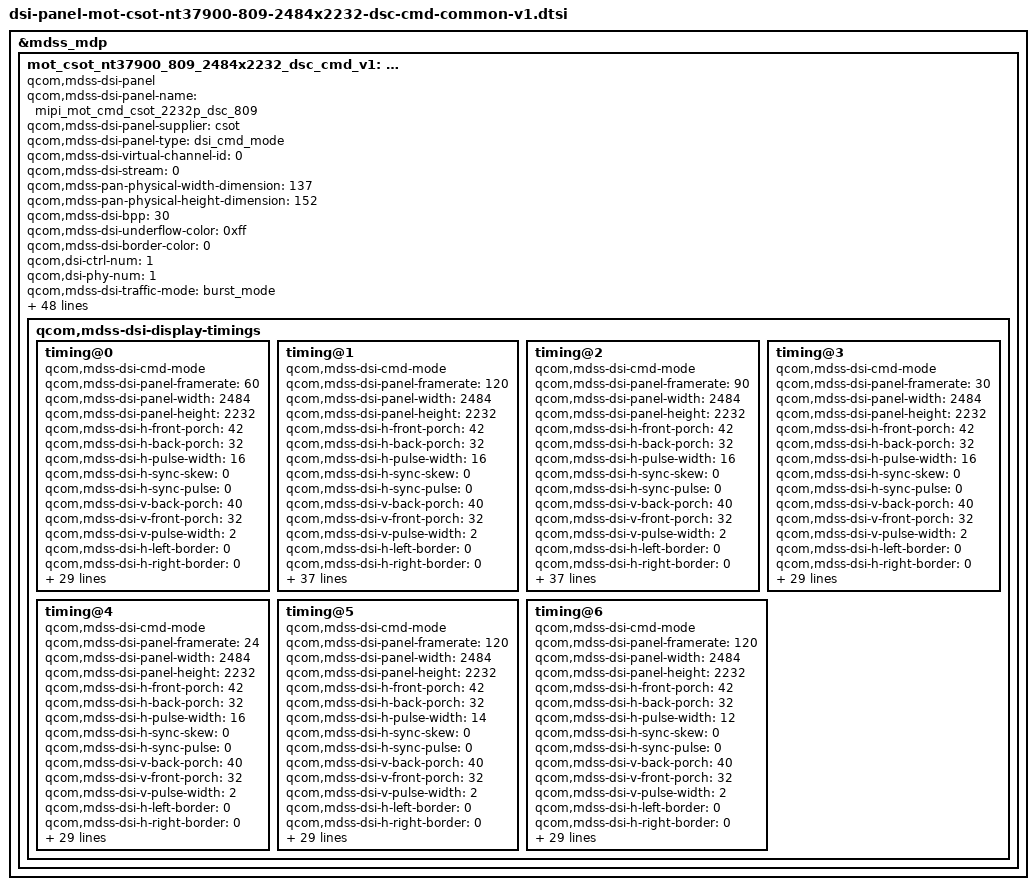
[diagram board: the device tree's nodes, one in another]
/* Copyright (c) 2019-2020, The Linux Foundation. All rights reserved.
 *
 * This program is free software; you can redistribute it and/or modify
 * it under the terms of the GNU General Public License version 2 and
 * only version 2 as published by the Free Software Foundation.
 *
 * This program is distributed in the hope that it will be useful,
 * but WITHOUT ANY WARRANTY; without even the implied warranty of
 * MERCHANTABILITY or FITNESS FOR A PARTICULAR PURPOSE.  See the
 * GNU General Public License for more details.
 */
&mdss_mdp {
mot_csot_nt37900_809_2484x2232_dsc_cmd_v1: qcom,mdss_dsi_mot_csot_nt37900_809_2484x2232_dsc_cmd_v1 {
compatible = "qcom,mdss-dsi-panel";
qcom,mdss-dsi-panel-name = "mipi_mot_cmd_csot_2232p_dsc_809";
qcom,mdss-dsi-panel-supplier = "csot";
qcom,mdss-dsi-panel-type = "dsi_cmd_mode";
qcom,mdss-dsi-virtual-channel-id = <0>;
qcom,mdss-dsi-stream = <0>;
qcom,mdss-pan-physical-width-dimension = <137>;
qcom,mdss-pan-physical-height-dimension = <152>;
qcom,mdss-dsi-bpp = <30>;
qcom,mdss-dsi-underflow-color = <0xff>;
qcom,mdss-dsi-border-color = <0>;

qcom,dsi-ctrl-num = <1>;
qcom,dsi-phy-num = <1>;

qcom,mdss-dsi-traffic-mode = "burst_mode";
qcom,mdss-dsi-bllp-eof-power-mode;
qcom,mdss-dsi-bllp-power-mode;
qcom,mdss-dsi-lane-0-state;
qcom,mdss-dsi-lane-1-state;
qcom,mdss-dsi-lane-2-state;
qcom,mdss-dsi-lane-3-state;

qcom,mdss-dsi-dma-trigger = "trigger_sw";
qcom,mdss-dsi-mdp-trigger = "none";
qcom,mdss-dsi-reset-sequence = <0 3>, <1 1>, <0 1>, <1 20>;
qcom,mdss-dsi-lp11-init;
qcom,mdss-dsi-tx-eot-append;
qcom,mdss-dsi-te-pin-select = <1>;
qcom,mdss-dsi-te-dcs-command = <1>;
qcom,mdss-dsi-te-using-te-pin;

qcom,mdss-dsi-panel-hdr-enabled;
qcom,mdss-dsi-panel-hdr-color-primaries = <14500 15500 32000
	        17000 15500 30000 8000 3000>;
qcom,mdss-dsi-panel-peak-brightness = <4200000>;

qcom,mdss-dsi-panel-blackness-level = <3230>;

qcom,mdss-dsi-dc-off-command = [
		39 00 00 40 00 00 02 6F 01
		39 00 00 00 00 00 02 8B 00
		];

qcom,mdss-dsi-dc-off-command-state = "dsi_hs_mode";
qcom,mdss-dsi-dc-on-command = [
		39 00 00 40 00 00 02 6F 01
		39 00 00 00 00 00 02 8B 81
		];
qcom,mdss-dsi-dc-on-command-state = "dsi_hs_mode";
//qcom,mdss-dsi-nt37705-dc-detect-fps;

qcom,check_pcd;
qcom,pcd-reg-read-enabled;
qcom,pcd-reg-check-before-read;
qcom,mdss-dsi-panel-pcd-reg-read-length = <1>;
qcom,mdss-dsi-panel-pcd-reg-mask = <0xFF>;
qcom,mdss-dsi-panel-pcd-reg-command = [06 01 00 01 00 00 01 D0];
qcom,mdss-dsi-panel-pcd-reg-pass-array-size = <4>;
qcom,mdss-dsi-panel-pcd-reg-pass-array = <0x80 0x81 0x82 0x83>;
qcom,mdss-dsi-panel-pcd-reg-read-delay-ms = <60>;
qcom,mdss-dsi-panel-pcd-reg-seq-interval = <30>; //pcd reg read seq interval per screen on.
qcom,mdss-dsi-panel-pcd-check-time-interval-in-minutes = <480>; //480 minutes/8hours for pcd reg read time interval

qcom,apl-enabled;
qcom,mdss-dsi-panel-APL-THRESHOLD-BL = <15412>;
qcom,mdss-dsi-panel-APL-FUNC-ID = <0>;
qcom,mdss-dsi-panel-apl-on-command = [
		39 00 00 00 00 00 02 5F 00
		];
qcom,mdss-dsi-panel-apl-off-command = [
		39 00 00 00 00 00 02 5F 10
		];

qcom,mdss-dsi-display-timings {

	timing@0{
		qcom,mdss-dsi-cmd-mode;
		qcom,mdss-dsi-panel-framerate = <60>;
		qcom,mdss-dsi-panel-width = <2484>;
		qcom,mdss-dsi-panel-height = <2232>;
		qcom,mdss-dsi-h-front-porch = <42>;
		qcom,mdss-dsi-h-back-porch = <32>;
		qcom,mdss-dsi-h-pulse-width = <16>;
		qcom,mdss-dsi-h-sync-skew = <0>;
		qcom,mdss-dsi-h-sync-pulse = <0>;
		qcom,mdss-dsi-v-back-porch = <40>;
		qcom,mdss-dsi-v-front-porch = <32>;
		qcom,mdss-dsi-v-pulse-width = <2>;
		qcom,mdss-dsi-h-left-border = <0>;
		qcom,mdss-dsi-h-right-border = <0>;
		qcom,mdss-dsi-v-top-border = <0>;
		qcom,mdss-dsi-v-bottom-border = <0>;
		qcom,mdss-dsi-timing-switch-command = [
			39 00 00 40 00 00 06 F0 55 AA 52 08 00
			39 00 00 40 00 00 02 6F CC
			39 00 00 40 00 00 02 B2 00
			39 00 00 40 00 00 02 6B 00
			39 00 00 40 00 00 02 6F 04
			39 00 00 40 00 00 02 35 00
			39 00 00 40 00 00 02 53 20
			39 00 00 40 00 00 02 5A 02
			39 00 00 40 00 00 02 2F 30
			39 00 00 40 00 00 03 6D 00 00
			39 00 00 40 00 00 02 6F 06
			39 00 00 40 00 00 02 6D 03
			39 00 00 40 00 00 06 F0 55 AA 52 08 00
			39 00 00 40 00 00 02 6F DE
			39 00 00 40 00 00 02 BA 04
			39 00 00 40 00 00 02 6F 08
			39 00 00 40 00 00 02 B2 C0
			39 00 00 00 11 00 02 8C 02
		];
		qcom,mdss-dsi-on-command = [
		39 00 00 40 00 00 06 F0 55 AA 52 08 04
		39 00 00 40 00 00 02 C2 12
		39 00 00 40 00 00 02 6F 01
		39 00 00 40 00 00 03 B5 00 00
		39 00 00 40 00 00 02 6F 03
		39 00 00 40 00 00 02 B5 07
		39 00 00 40 00 00 02 6F 00
		39 00 00 40 00 00 04 B8 3B 00 00
		39 00 00 40 00 00 02 6F 03
		39 00 00 40 00 00 03 B8 FF DC
		39 00 00 40 00 00 02 6F 05
		39 00 00 40 00 00 04 B8 3C 00 00
		39 00 00 40 00 00 02 6F 08
		39 00 00 40 00 00 03 B8 FF DC
		39 00 00 40 00 00 02 6F 0A
		39 00 00 40 00 00 04 B8 3D 00 00
		39 00 00 40 00 00 02 6F 0D
		39 00 00 00 00 00 03 B8 FF DC
		39 00 00 00 14 00 02 9D AA
		39 00 00 00 00 00 06 F0 55 AA 52 08 04
		39 00 00 40 00 00 02 C2 11
		39 00 00 40 00 00 02 6F 01
		39 00 00 40 00 00 03 B5 00 14
		39 00 00 40 00 00 02 6F 0C
		39 00 00 40 00 00 04 B6 00 00 00
		39 00 00 40 00 00 02 6F 0F
		39 00 00 40 00 00 04 B6 1C AB 80
		39 00 00 40 00 00 02 6F 18
		39 00 00 40 00 00 04 B6 1D 00 00
		39 00 00 40 00 00 02 6F 1B
		39 00 00 40 00 00 04 B6 0D D5 80
		39 00 00 40 00 00 02 6F 03
		39 00 00 40 00 00 02 B5 03
		39 00 00 40 00 00 02 6F 00
		39 00 00 40 00 00 04 B8 2B 00 00
		39 00 00 40 00 00 02 6F 03
		39 00 00 40 00 00 03 B8 0F FE
		39 00 00 40 00 00 02 6F 05
		39 00 00 40 00 00 04 B8 2B 10 00
		39 00 00 40 00 00 02 6F 08
		39 00 00 40 00 00 03 B8 03 A3
		39 00 00 40 00 00 02 6F 0A
		39 00 00 40 00 00 04 B8 2B 20 00
		39 00 00 40 00 00 02 6F 0D
		39 00 00 40 00 00 03 B8 00 4F
		39 00 00 40 00 00 02 6F 0F
		39 00 00 40 00 00 04 B8 2B 30 00
		39 00 00 40 00 00 02 6F 12
		39 00 00 40 00 00 03 B8 03 A3
		39 00 00 00 00 00 06 F0 55 AA 52 08 04
		39 00 00 40 00 00 02 6F 06
		39 00 00 40 00 00 02 B5 00
		39 00 00 40 00 00 05 FF AA 55 A5 81
		39 00 00 40 00 00 02 6F 0C
		39 00 00 40 00 00 02 FD 40
		39 00 00 40 00 00 03 51 00 00
		39 00 00 40 00 00 06 A3 84 4D BF CD BF
		39 00 00 40 00 00 06 F0 55 AA 52 08 00
		39 00 00 40 00 00 02 6F 30
		39 00 00 40 00 00 02 C0 38
		39 00 00 40 00 00 02 6F 59
		39 00 00 40 00 00 04 D5 00 1F 00
		39 00 00 40 00 00 06 F0 55 AA 52 08 00
		39 00 00 40 00 00 02 6F 1C
		39 00 00 40 00 00 11 BA 01 01 01 01 01 00 00 00 01 00 00 00 00 00 00 00
		39 00 00 40 00 00 06 F0 55 AA 52 08 01
		39 00 00 40 00 00 02 DD 5E
		39 00 00 40 00 00 06 F0 55 AA 52 08 00
		39 00 00 40 00 00 03 B2 09 60
		39 00 00 40 00 00 06 F0 55 AA 52 08 01
		39 00 00 40 00 00 02 6F 03
		39 00 00 40 00 00 02 C7 47
		39 00 00 40 00 00 06 F0 55 AA 52 08 01
		39 00 00 40 00 00 02 6F 41
		39 00 00 40 00 00 02 BB 57
		39 00 00 40 00 00 02 6F 47
		39 00 00 40 00 00 02 BB 4A
		39 00 00 40 00 00 02 6F 5F
		39 00 00 40 00 00 02 BB 57
		39 00 00 40 00 00 02 6F 65
		39 00 00 40 00 00 02 BB 4A
		39 00 00 40 00 00 05 FF AA 55 A5 80
		39 00 00 40 00 00 02 6F 29
		39 00 00 40 00 00 03 F8 0B B5
		39 00 00 40 00 00 02 6F 0D
		39 00 00 40 00 00 03 F8 01 3E
		39 00 00 40 00 00 02 6F 08
		39 00 00 40 00 00 08 F6 70 07 70 70 70 70 70
		39 00 00 40 00 00 02 68 00
		39 00 00 40 00 00 02 6F 01
		39 00 00 40 00 00 05 6B 01 E8 05 D0
		39 00 00 40 00 00 02 6F 05
		39 00 00 40 00 00 02 6D 77
		39 00 00 40 00 00 05 FF AA 55 A5 81
		39 00 00 40 00 00 02 6F 0A
		39 00 00 40 00 00 02 FD 00
		39 00 00 40 00 00 02 6F 0D
		39 00 00 40 00 00 02 FB 80
		39 00 00 40 00 00 02 6F 0D
		39 00 00 40 00 00 02 FE 83
		39 00 00 40 00 00 02 6F 10
		39 00 00 40 00 00 03 FE 07 FF
		39 00 00 40 00 00 05 FF AA 55 A5 82
		39 00 00 40 00 00 02 6F 11
		39 00 00 40 00 00 02 F8 0F
		39 00 00 40 00 00 02 17 30
		39 00 00 40 00 00 02 26 00
		39 00 00 40 00 00 02 5F 10
		39 00 00 40 00 00 02 2F 00
		39 00 00 40 00 00 05 2A 00 00 09 B3
		39 00 00 40 00 00 05 2B 00 00 08 B7

		39 00 00 40 00 00 06 F0 55 AA 52 08 00
		39 00 00 40 00 00 02 6F CC
		39 00 00 40 00 00 02 B2 00
		39 00 00 40 00 00 02 6F 04
		39 00 00 40 00 00 02 35 00
		39 00 00 40 00 00 02 53 20
		39 00 00 40 00 00 02 5A 02
		39 00 00 40 00 00 02 2F 30
		39 00 00 40 00 00 03 6D 00 00
		39 00 00 40 00 00 02 6F 06
		39 00 00 40 00 00 02 6D 03
		39 00 00 40 00 00 06 F0 55 AA 52 08 00
		39 00 00 40 00 00 02 6F DE
		39 00 00 40 00 00 02 BA 04
		39 00 00 40 00 00 02 6F 08
		39 00 00 40 00 00 02 B2 C0
		39 00 00 00 00 00 02 8C 02

		39 00 00 40 00 00 03 90 03 43
		39 00 00 40 00 00 13 91 AB 28 00 08 C2 00 03 6D 01 01 00 11 0D B7 05 87 10 F0
		39 00 00 40 00 00 05 FF AA 55 A5 84
		39 00 00 00 00 00 02 F2 15
                05 00 00 00 78 00 01 11
		39 00 00 40 00 00 06 A3 84 4D BF CD BF
		39 00 00 40 00 00 02 6F 05
		39 00 00 40 00 00 0E A3 02 04 B5 02 03 00 03 00 00 00 00 00 00
		39 00 00 40 00 00 02 6F 12
		39 00 00 40 00 00 07 A3 01 00 9D 00 00 AA
		39 00 00 40 00 00 02 6F A1
		39 00 00 40 00 00 0E A3 02 04 B5 02 03 00 0C 00 00 00 00 00 00
		39 00 00 40 00 00 02 6F AE
		39 00 00 40 00 00 07 A3 01 00 9D 00 00 AA
                05 00 00 00 00 00 01 29];	/* display on */
		qcom,mdss-dsi-off-command = [
			05 00 00 00 00 00 01 28		/* display_off */
			05 00 00 00 78 00 01 10];	/* enter sleep mode */

		qcom,mdss-dsi-on-command-state = "dsi_lp_mode";
		qcom,mdss-dsi-off-command-state = "dsi_lp_mode";
		qcom,mdss-dsi-timing-switch-command-state =
			"dsi_hs_mode";
		qcom,compression-mode = "dsc";
		/* Why QCOM doesn't use this, even it used 2 encoder
		 * as for that dsi_sw43404_amoled_cmd, for ex */
		/* qcom,mdss-dsc-encoders = <2>; */
		qcom,mdss-dsc-version = <0x11>;
		qcom,mdss-dsc-slice-height = <8>;
		qcom,mdss-dsc-slice-width = <1242>;
		qcom,mdss-dsc-slice-per-pkt = <2>;
		qcom,mdss-dsc-bit-per-component = <10>;
		qcom,mdss-dsc-bit-per-pixel = <8>;
		qcom,mdss-dsc-block-prediction-enable;
		qcom,mdss-dsc-novateck-ic;

		qcom,mdss-dsi-pcd-check-enable-command = [
			39 00 00 40 00 00 06 F0 55 AA 52 08 01
			39 00 00 40 00 00 02 6F 01
			39 00 00 00 00 00 06 D0 80 00 30 00 01
			];
		qcom,mdss-dsi-pcd-check-enable-command-state = "dsi_hs_mode";
		qcom,mdss-dsi-pcd-check-disable-command = [
			39 00 00 40 00 00 06 F0 55 AA 52 08 01
			39 00 00 40 00 00 02 6F 01
			39 00 00 00 00 00 06 D0 00 00 30 00 01
			];
		qcom,mdss-dsi-pcd-check-disable-command-state = "dsi_hs_mode";
	};

	timing@1{
		qcom,mdss-dsi-cmd-mode;
		qcom,mdss-dsi-panel-framerate = <120>;
		qcom,mdss-dsi-panel-width = <2484>;
		qcom,mdss-dsi-panel-height = <2232>;
		qcom,mdss-dsi-h-front-porch = <42>;
		qcom,mdss-dsi-h-back-porch = <32>;
		qcom,mdss-dsi-h-pulse-width = <16>;
		qcom,mdss-dsi-h-sync-skew = <0>;
		qcom,mdss-dsi-h-sync-pulse = <0>;
		qcom,mdss-dsi-v-back-porch = <40>;
		qcom,mdss-dsi-v-front-porch = <32>;
		qcom,mdss-dsi-v-pulse-width = <2>;
		qcom,mdss-dsi-h-left-border = <0>;
		qcom,mdss-dsi-h-right-border = <0>;
		qcom,mdss-dsi-v-top-border = <0>;
		qcom,mdss-dsi-v-bottom-border = <0>;
		qcom,mdss-dsi-timing-switch-command = [
			39 00 00 40 00 00 02 6B 00
			39 00 00 40 00 00 02 6F 04
			39 00 00 40 00 00 02 35 00
			39 00 00 40 00 00 02 53 20
			39 00 00 40 00 00 02 2F 00
			39 00 00 40 00 00 06 F0 55 AA 52 08 00
			39 00 00 40 00 00 02 6F CC
			39 00 00 00 00 00 02 B2 00
		];
		qcom,mdss-dsi-on-command = [
		39 00 00 40 00 00 06 F0 55 AA 52 08 04
		39 00 00 40 00 00 02 C2 12
		39 00 00 40 00 00 02 6F 01
		39 00 00 40 00 00 03 B5 00 00
		39 00 00 40 00 00 02 6F 03
		39 00 00 40 00 00 02 B5 07
		39 00 00 40 00 00 02 6F 00
		39 00 00 40 00 00 04 B8 3B 00 00
		39 00 00 40 00 00 02 6F 03
		39 00 00 40 00 00 03 B8 FF DC
		39 00 00 40 00 00 02 6F 05
		39 00 00 40 00 00 04 B8 3C 00 00
		39 00 00 40 00 00 02 6F 08
		39 00 00 40 00 00 03 B8 FF DC
		39 00 00 40 00 00 02 6F 0A
		39 00 00 40 00 00 04 B8 3D 00 00
		39 00 00 40 00 00 02 6F 0D
		39 00 00 00 00 00 03 B8 FF DC
		39 00 00 00 14 00 02 9D AA
		39 00 00 00 00 00 06 F0 55 AA 52 08 04
		39 00 00 40 00 00 02 C2 11
		39 00 00 40 00 00 02 6F 01
		39 00 00 40 00 00 03 B5 00 14
		39 00 00 40 00 00 02 6F 0C
		39 00 00 40 00 00 04 B6 00 00 00
		39 00 00 40 00 00 02 6F 0F
		39 00 00 40 00 00 04 B6 1C AB 80
		39 00 00 40 00 00 02 6F 18
		39 00 00 40 00 00 04 B6 1D 00 00
		39 00 00 40 00 00 02 6F 1B
		39 00 00 40 00 00 04 B6 0D D5 80
		39 00 00 40 00 00 02 6F 03
		39 00 00 40 00 00 02 B5 03
		39 00 00 40 00 00 02 6F 00
		39 00 00 40 00 00 04 B8 2B 00 00
		39 00 00 40 00 00 02 6F 03
		39 00 00 40 00 00 03 B8 0F FE
		39 00 00 40 00 00 02 6F 05
		39 00 00 40 00 00 04 B8 2B 10 00
		39 00 00 40 00 00 02 6F 08
		39 00 00 40 00 00 03 B8 03 A3
		39 00 00 40 00 00 02 6F 0A
		39 00 00 40 00 00 04 B8 2B 20 00
		39 00 00 40 00 00 02 6F 0D
		39 00 00 40 00 00 03 B8 00 4F
		39 00 00 40 00 00 02 6F 0F
		39 00 00 40 00 00 04 B8 2B 30 00
		39 00 00 40 00 00 02 6F 12
		39 00 00 40 00 00 03 B8 03 A3
		39 00 00 00 00 00 06 F0 55 AA 52 08 04
		39 00 00 40 00 00 02 6F 06
		39 00 00 40 00 00 02 B5 00
		39 00 00 40 00 00 05 FF AA 55 A5 81
		39 00 00 40 00 00 02 6F 0C
		39 00 00 40 00 00 02 FD 40
		39 00 00 40 00 00 03 51 00 00
		39 00 00 40 00 00 06 A3 84 4D BF CD BF
		39 00 00 40 00 00 06 F0 55 AA 52 08 00
		39 00 00 40 00 00 02 6F 30
		39 00 00 40 00 00 02 C0 38
		39 00 00 40 00 00 02 6F 59
		39 00 00 40 00 00 04 D5 00 1F 00
		39 00 00 40 00 00 06 F0 55 AA 52 08 00
		39 00 00 40 00 00 02 6F 1C
		39 00 00 40 00 00 11 BA 01 01 01 01 01 00 00 00 01 00 00 00 00 00 00 00
		39 00 00 40 00 00 06 F0 55 AA 52 08 01
		39 00 00 40 00 00 02 DD 5E
		39 00 00 40 00 00 06 F0 55 AA 52 08 00
		39 00 00 40 00 00 03 B2 09 60
		39 00 00 40 00 00 06 F0 55 AA 52 08 01
		39 00 00 40 00 00 02 6F 03
		39 00 00 40 00 00 02 C7 47
		39 00 00 40 00 00 06 F0 55 AA 52 08 01
		39 00 00 40 00 00 02 6F 41
		39 00 00 40 00 00 02 BB 57
		39 00 00 40 00 00 02 6F 47
		39 00 00 40 00 00 02 BB 4A
		39 00 00 40 00 00 02 6F 5F
		39 00 00 40 00 00 02 BB 57
		39 00 00 40 00 00 02 6F 65
		39 00 00 40 00 00 02 BB 4A
		39 00 00 40 00 00 05 FF AA 55 A5 80
		39 00 00 40 00 00 02 6F 29
		39 00 00 40 00 00 03 F8 0B B5
		39 00 00 40 00 00 02 6F 0D
		39 00 00 40 00 00 03 F8 01 3E
		39 00 00 40 00 00 02 6F 08
		39 00 00 40 00 00 08 F6 70 07 70 70 70 70 70
		39 00 00 40 00 00 02 68 00
		39 00 00 40 00 00 02 6F 01
		39 00 00 40 00 00 05 6B 01 E8 05 D0
		39 00 00 40 00 00 02 6F 05
		39 00 00 40 00 00 02 6D 77
		39 00 00 40 00 00 05 FF AA 55 A5 81
		39 00 00 40 00 00 02 6F 0A
		39 00 00 40 00 00 02 FD 00
		39 00 00 40 00 00 02 6F 0D
		39 00 00 40 00 00 02 FB 80
		39 00 00 40 00 00 02 6F 0D
		39 00 00 40 00 00 02 FE 83
		39 00 00 40 00 00 02 6F 10
		39 00 00 40 00 00 03 FE 07 FF
		39 00 00 40 00 00 05 FF AA 55 A5 82
		39 00 00 40 00 00 02 6F 11
		39 00 00 40 00 00 02 F8 0F
		39 00 00 40 00 00 02 17 30
		39 00 00 40 00 00 02 26 00
		39 00 00 40 00 00 02 5F 10
		39 00 00 40 00 00 02 2F 00
		39 00 00 40 00 00 05 2A 00 00 09 B3
		39 00 00 40 00 00 05 2B 00 00 08 B7

		39 00 00 40 00 00 02 6F 04
		39 00 00 40 00 00 02 35 00
		39 00 00 40 00 00 02 53 20
		39 00 00 40 00 00 02 2F 00
		39 00 00 40 00 00 06 F0 55 AA 52 08 00
		39 00 00 40 00 00 02 6F CC
		39 00 00 00 00 00 02 B2 00

		39 00 00 40 00 00 03 90 03 43
		39 00 00 40 00 00 13 91 AB 28 00 08 C2 00 03 6D 01 01 00 11 0D B7 05 87 10 F0
		39 00 00 40 00 00 05 FF AA 55 A5 84
		39 00 00 00 00 00 02 F2 15
                05 00 00 00 78 00 01 11
		39 00 00 40 00 00 06 A3 84 4D BF CD BF
		39 00 00 40 00 00 02 6F 05
		39 00 00 40 00 00 0E A3 02 04 B5 02 03 00 03 00 00 00 00 00 00
		39 00 00 40 00 00 02 6F 12
		39 00 00 40 00 00 07 A3 01 00 9D 00 00 AA
		39 00 00 40 00 00 02 6F A1
		39 00 00 40 00 00 0E A3 02 04 B5 02 03 00 0C 00 00 00 00 00 00
		39 00 00 40 00 00 02 6F AE
		39 00 00 40 00 00 07 A3 01 00 9D 00 00 AA
                05 00 00 00 00 00 01 29];	/* display on */
		qcom,mdss-dsi-off-command = [
			05 00 00 00 00 00 01 28		/* display_off */
			05 00 00 00 78 00 01 10];	/* enter sleep mode */

		qcom,mdss-dsi-on-command-state = "dsi_lp_mode";
		qcom,mdss-dsi-off-command-state = "dsi_lp_mode";
		qcom,mdss-dsi-timing-switch-command-state =
			"dsi_hs_mode";
		qcom,compression-mode = "dsc";
		/* Why QCOM doesn't use this, even it used 2 encoder
		 * as for that dsi_sw43404_amoled_cmd, for ex */
		/* qcom,mdss-dsc-encoders = <2>; */
		qcom,mdss-dsc-version = <0x11>;
		qcom,mdss-dsc-slice-height = <8>;
		qcom,mdss-dsc-slice-width = <1242>;
		qcom,mdss-dsc-slice-per-pkt = <2>;
		qcom,mdss-dsc-bit-per-component = <10>;
		qcom,mdss-dsc-bit-per-pixel = <8>;
		qcom,mdss-dsc-block-prediction-enable;
		qcom,mdss-dsc-novateck-ic;

		qcom,mdss-dsi-pcd-check-enable-command = [
			39 00 00 40 00 00 06 F0 55 AA 52 08 01
			39 00 00 40 00 00 02 6F 01
			39 00 00 00 00 00 06 D0 80 00 30 00 01
			];
		qcom,mdss-dsi-pcd-check-enable-command-state = "dsi_hs_mode";
		qcom,mdss-dsi-pcd-check-disable-command = [
			39 00 00 40 00 00 06 F0 55 AA 52 08 01
			39 00 00 40 00 00 02 6F 01
			39 00 00 00 00 00 06 D0 00 00 30 00 01
			];
		qcom,mdss-dsi-pcd-check-disable-command-state = "dsi_hs_mode";

		qcom,mdss-dsi-partition-refreshrate-off-command = [
			39 00 00 00 00 00 02 6B 00
		];

		qcom,mdss-dsi-partition-refreshrate-off-command-state = "dsi_hs_mode";
		qcom,mdss-dsi-partition-refreshrate-on-command = [
			39 00 00 40 00 00 06 F0 55 AA 52 08 00
			39 00 00 40 00 00 02 6F CC
			39 00 00 40 00 00 02 B2 00
			39 00 00 40 00 00 02 5A 00
			39 00 00 40 00 00 02 6B 00
			39 00 00 40 00 00 02 2F 00
			39 00 00 40 00 00 02 6F 01
			39 00 00 40 00 00 05 6B 02 E8 05 D0
			39 00 00 40 00 00 02 6F 10
			39 00 00 40 00 00 0f 6B 01 00 01 01 00 01 01 00 01 01 00 01 01 00
			39 00 00 40 00 00 02 6F 20
			39 00 00 40 00 00 0f 6B 01 00 01 01 00 01 01 00 01 01 00 01 01 00
			39 00 00 40 00 00 02 6F 30
			39 00 00 40 00 00 0f 6B 01 00 01 01 00 01 01 00 01 01 00 01 01 00
			39 00 00 00 00 00 02 6B 01
		];
		qcom,mdss-dsi-partition-refreshrate-on-command-state = "dsi_hs_mode";
	};

	timing@2{
		qcom,mdss-dsi-cmd-mode;
		qcom,mdss-dsi-panel-framerate = <90>;
		qcom,mdss-dsi-panel-width = <2484>;
		qcom,mdss-dsi-panel-height = <2232>;
		qcom,mdss-dsi-h-front-porch = <42>;
		qcom,mdss-dsi-h-back-porch = <32>;
		qcom,mdss-dsi-h-pulse-width = <16>;
		qcom,mdss-dsi-h-sync-skew = <0>;
		qcom,mdss-dsi-h-sync-pulse = <0>;
		qcom,mdss-dsi-v-back-porch = <40>;
		qcom,mdss-dsi-v-front-porch = <32>;
		qcom,mdss-dsi-v-pulse-width = <2>;
		qcom,mdss-dsi-h-left-border = <0>;
		qcom,mdss-dsi-h-right-border = <0>;
		qcom,mdss-dsi-v-top-border = <0>;
		qcom,mdss-dsi-v-bottom-border = <0>;
		qcom,mdss-dsi-timing-switch-command = [
			39 00 00 40 00 00 02 6B 00
			39 00 00 40 00 00 02 6F 04
			39 00 00 40 00 00 02 35 00
			39 00 00 40 00 00 02 53 20
			39 00 00 40 00 00 02 2F 01
			39 00 00 40 00 00 06 F0 55 AA 52 08 00
			39 00 00 40 00 00 02 6F CC
			39 00 00 00 0B 00 02 B2 00
		];
		qcom,mdss-dsi-on-command = [
		39 00 00 40 00 00 06 F0 55 AA 52 08 04
		39 00 00 40 00 00 02 C2 12
		39 00 00 40 00 00 02 6F 01
		39 00 00 40 00 00 03 B5 00 00
		39 00 00 40 00 00 02 6F 03
		39 00 00 40 00 00 02 B5 07
		39 00 00 40 00 00 02 6F 00
		39 00 00 40 00 00 04 B8 3B 00 00
		39 00 00 40 00 00 02 6F 03
		39 00 00 40 00 00 03 B8 FF DC
		39 00 00 40 00 00 02 6F 05
		39 00 00 40 00 00 04 B8 3C 00 00
		39 00 00 40 00 00 02 6F 08
		39 00 00 40 00 00 03 B8 FF DC
		39 00 00 40 00 00 02 6F 0A
		39 00 00 40 00 00 04 B8 3D 00 00
		39 00 00 40 00 00 02 6F 0D
		39 00 00 00 00 00 03 B8 FF DC
		39 00 00 00 14 00 02 9D AA
		39 00 00 00 00 00 06 F0 55 AA 52 08 04
		39 00 00 40 00 00 02 C2 11
		39 00 00 40 00 00 02 6F 01
		39 00 00 40 00 00 03 B5 00 14
		39 00 00 40 00 00 02 6F 0C
		39 00 00 40 00 00 04 B6 00 00 00
		39 00 00 40 00 00 02 6F 0F
		39 00 00 40 00 00 04 B6 1C AB 80
		39 00 00 40 00 00 02 6F 18
		39 00 00 40 00 00 04 B6 1D 00 00
		39 00 00 40 00 00 02 6F 1B
		39 00 00 40 00 00 04 B6 0D D5 80
		39 00 00 40 00 00 02 6F 03
		39 00 00 40 00 00 02 B5 03
		39 00 00 40 00 00 02 6F 00
		39 00 00 40 00 00 04 B8 2B 00 00
		39 00 00 40 00 00 02 6F 03
		39 00 00 40 00 00 03 B8 0F FE
		39 00 00 40 00 00 02 6F 05
		39 00 00 40 00 00 04 B8 2B 10 00
		39 00 00 40 00 00 02 6F 08
		39 00 00 40 00 00 03 B8 03 A3
		39 00 00 40 00 00 02 6F 0A
		39 00 00 40 00 00 04 B8 2B 20 00
		39 00 00 40 00 00 02 6F 0D
		39 00 00 40 00 00 03 B8 00 4F
		39 00 00 40 00 00 02 6F 0F
		39 00 00 40 00 00 04 B8 2B 30 00
		39 00 00 40 00 00 02 6F 12
		39 00 00 40 00 00 03 B8 03 A3
		39 00 00 00 00 00 06 F0 55 AA 52 08 04
		39 00 00 40 00 00 02 6F 06
		39 00 00 40 00 00 02 B5 00
		39 00 00 40 00 00 05 FF AA 55 A5 81
		39 00 00 40 00 00 02 6F 0C
		39 00 00 40 00 00 02 FD 40
		39 00 00 40 00 00 03 51 00 00
		39 00 00 40 00 00 06 A3 84 4D BF CD BF
		39 00 00 40 00 00 06 F0 55 AA 52 08 00
		39 00 00 40 00 00 02 6F 30
		39 00 00 40 00 00 02 C0 38
		39 00 00 40 00 00 02 6F 59
		39 00 00 40 00 00 04 D5 00 1F 00
		39 00 00 40 00 00 06 F0 55 AA 52 08 00
		39 00 00 40 00 00 02 6F 1C
		39 00 00 40 00 00 11 BA 01 01 01 01 01 00 00 00 01 00 00 00 00 00 00 00
		39 00 00 40 00 00 06 F0 55 AA 52 08 01
		39 00 00 40 00 00 02 DD 5E
		39 00 00 40 00 00 06 F0 55 AA 52 08 00
		39 00 00 40 00 00 03 B2 09 60
		39 00 00 40 00 00 06 F0 55 AA 52 08 01
		39 00 00 40 00 00 02 6F 03
		39 00 00 40 00 00 02 C7 47
		39 00 00 40 00 00 06 F0 55 AA 52 08 01
		39 00 00 40 00 00 02 6F 41
		39 00 00 40 00 00 02 BB 57
		39 00 00 40 00 00 02 6F 47
		39 00 00 40 00 00 02 BB 4A
		39 00 00 40 00 00 02 6F 5F
		39 00 00 40 00 00 02 BB 57
		39 00 00 40 00 00 02 6F 65
		39 00 00 40 00 00 02 BB 4A
		39 00 00 40 00 00 05 FF AA 55 A5 80
		39 00 00 40 00 00 02 6F 29
		39 00 00 40 00 00 03 F8 0B B5
		39 00 00 40 00 00 02 6F 0D
		39 00 00 40 00 00 03 F8 01 3E
		39 00 00 40 00 00 02 6F 08
		39 00 00 40 00 00 08 F6 70 07 70 70 70 70 70
		39 00 00 40 00 00 02 68 00
		39 00 00 40 00 00 02 6F 01
		39 00 00 40 00 00 05 6B 01 E8 05 D0
		39 00 00 40 00 00 02 6F 05
		39 00 00 40 00 00 02 6D 77
		39 00 00 40 00 00 05 FF AA 55 A5 81
		39 00 00 40 00 00 02 6F 0A
		39 00 00 40 00 00 02 FD 00
		39 00 00 40 00 00 02 6F 0D
		39 00 00 40 00 00 02 FB 80
		39 00 00 40 00 00 02 6F 0D
		39 00 00 40 00 00 02 FE 83
		39 00 00 40 00 00 02 6F 10
		39 00 00 40 00 00 03 FE 07 FF
		39 00 00 40 00 00 05 FF AA 55 A5 82
		39 00 00 40 00 00 02 6F 11
		39 00 00 40 00 00 02 F8 0F
		39 00 00 40 00 00 02 17 30
		39 00 00 40 00 00 02 26 00
		39 00 00 40 00 00 02 5F 10
		39 00 00 40 00 00 02 2F 00
		39 00 00 40 00 00 05 2A 00 00 09 B3
		39 00 00 40 00 00 05 2B 00 00 08 B7

		39 00 00 40 00 00 02 6F 04
		39 00 00 40 00 00 02 35 00
		39 00 00 40 00 00 02 53 20
		39 00 00 40 00 00 02 2F 01
		39 00 00 40 00 00 06 F0 55 AA 52 08 00
		39 00 00 40 00 00 02 6F CC
		39 00 00 00 00 00 02 B2 00

		39 00 00 40 00 00 03 90 03 43
		39 00 00 40 00 00 13 91 AB 28 00 08 C2 00 03 6D 01 01 00 11 0D B7 05 87 10 F0
		39 00 00 40 00 00 05 FF AA 55 A5 84
		39 00 00 00 00 00 02 F2 15
                05 00 00 00 78 00 01 11
		39 00 00 40 00 00 06 A3 84 4D BF CD BF
		39 00 00 40 00 00 02 6F 05
		39 00 00 40 00 00 0E A3 02 04 B5 02 03 00 03 00 00 00 00 00 00
		39 00 00 40 00 00 02 6F 12
		39 00 00 40 00 00 07 A3 01 00 9D 00 00 AA
		39 00 00 40 00 00 02 6F A1
		39 00 00 40 00 00 0E A3 02 04 B5 02 03 00 0C 00 00 00 00 00 00
		39 00 00 40 00 00 02 6F AE
		39 00 00 40 00 00 07 A3 01 00 9D 00 00 AA
                05 00 00 00 00 00 01 29];	/* display on */
		qcom,mdss-dsi-off-command = [
			05 00 00 00 00 00 01 28		/* display_off */
			05 00 00 00 78 00 01 10];	/* enter sleep mode */

		qcom,mdss-dsi-on-command-state = "dsi_lp_mode";
		qcom,mdss-dsi-off-command-state = "dsi_lp_mode";
		qcom,mdss-dsi-timing-switch-command-state =
			"dsi_hs_mode";
		qcom,compression-mode = "dsc";
		/* Why QCOM doesn't use this, even it used 2 encoder
		 * as for that dsi_sw43404_amoled_cmd, for ex */
		/* qcom,mdss-dsc-encoders = <2>; */
		qcom,mdss-dsc-version = <0x11>;
		qcom,mdss-dsc-slice-height = <8>;
		qcom,mdss-dsc-slice-width = <1242>;
		qcom,mdss-dsc-slice-per-pkt = <2>;
		qcom,mdss-dsc-bit-per-component = <10>;
		qcom,mdss-dsc-bit-per-pixel = <8>;
		qcom,mdss-dsc-block-prediction-enable;
		qcom,mdss-dsc-novateck-ic;


		qcom,mdss-dsi-pcd-check-enable-command = [
			39 00 00 40 00 00 06 F0 55 AA 52 08 01
			39 00 00 40 00 00 02 6F 01
			39 00 00 00 00 00 06 D0 80 00 30 00 01
			];
		qcom,mdss-dsi-pcd-check-enable-command-state = "dsi_hs_mode";
		qcom,mdss-dsi-pcd-check-disable-command = [
			39 00 00 40 00 00 06 F0 55 AA 52 08 01
			39 00 00 40 00 00 02 6F 01
			39 00 00 00 00 00 06 D0 00 00 30 00 01
			];
		qcom,mdss-dsi-pcd-check-disable-command-state = "dsi_hs_mode";

		qcom,mdss-dsi-partition-refreshrate-off-command = [
			39 00 00 00 00 00 02 6B 00
		];

		qcom,mdss-dsi-partition-refreshrate-off-command-state = "dsi_hs_mode";
		qcom,mdss-dsi-partition-refreshrate-on-command = [
			39 00 00 40 00 00 06 F0 55 AA 52 08 00
			39 00 00 40 00 00 02 6F CC
			39 00 00 40 00 00 02 B2 00
			39 00 00 40 00 00 02 5A 00
			39 00 00 40 00 00 02 6B 00
			39 00 00 40 00 00 02 2F 01
			39 00 00 40 00 00 02 6F 01
			39 00 00 40 00 00 05 6B 02 E8 05 D0
			39 00 00 40 00 00 02 6F 10
			39 00 00 40 00 00 0f 6B 01 00 01 01 00 01 01 00 01 01 00 01 01 00
			39 00 00 40 00 00 02 6F 20
			39 00 00 40 00 00 0f 6B 01 00 01 01 00 01 01 00 01 01 00 01 01 00
			39 00 00 40 00 00 02 6F 30
			39 00 00 40 00 00 0f 6B 01 00 01 01 00 01 01 00 01 01 00 01 01 00
			39 00 00 00 00 00 02 6B 01
		];
		qcom,mdss-dsi-partition-refreshrate-on-command-state = "dsi_hs_mode";
	};

	timing@3{
		qcom,mdss-dsi-cmd-mode;
		qcom,mdss-dsi-panel-framerate = <30>;
		qcom,mdss-dsi-panel-width = <2484>;
		qcom,mdss-dsi-panel-height = <2232>;
		qcom,mdss-dsi-h-front-porch = <42>;
		qcom,mdss-dsi-h-back-porch = <32>;
		qcom,mdss-dsi-h-pulse-width = <16>;
		qcom,mdss-dsi-h-sync-skew = <0>;
		qcom,mdss-dsi-h-sync-pulse = <0>;
		qcom,mdss-dsi-v-back-porch = <40>;
		qcom,mdss-dsi-v-front-porch = <32>;
		qcom,mdss-dsi-v-pulse-width = <2>;
		qcom,mdss-dsi-h-left-border = <0>;
		qcom,mdss-dsi-h-right-border = <0>;
		qcom,mdss-dsi-v-top-border = <0>;
		qcom,mdss-dsi-v-bottom-border = <0>;
		qcom,mdss-dsi-timing-switch-command = [
			39 00 00 40 00 00 06 F0 55 AA 52 08 00
			39 00 00 40 00 00 02 6F CC
			39 00 00 40 00 00 02 B2 00
			39 00 00 40 00 00 02 6B 00
			39 00 00 40 00 00 02 6F 04
			39 00 00 40 00 00 02 35 03
			39 00 00 40 00 00 02 53 28
			39 00 00 40 00 00 02 5A 00
			39 00 00 40 00 00 02 2F 30
			39 00 00 40 00 00 03 6D 01 01
			39 00 00 40 00 00 02 6F 06
			39 00 00 40 00 00 02 6D 00
			39 00 00 40 00 00 06 F0 55 AA 52 08 00
			39 00 00 40 00 00 02 6F DE
			39 00 00 40 00 00 02 BA 00
			39 00 00 40 00 00 02 6F 08
			39 00 00 40 00 00 02 B2 C0
			39 00 00 40 00 00 02 8C 00
			39 00 00 40 00 00 06 F0 55 AA 52 08 00
			39 00 00 40 00 00 02 6F 05
			39 00 00 00 00 00 03 B2 04 04
		];
		qcom,mdss-dsi-on-command = [
		39 00 00 40 00 00 06 F0 55 AA 52 08 04
		39 00 00 40 00 00 02 C2 12
		39 00 00 40 00 00 02 6F 01
		39 00 00 40 00 00 03 B5 00 00
		39 00 00 40 00 00 02 6F 03
		39 00 00 40 00 00 02 B5 07
		39 00 00 40 00 00 02 6F 00
		39 00 00 40 00 00 04 B8 3B 00 00
		39 00 00 40 00 00 02 6F 03
		39 00 00 40 00 00 03 B8 FF DC
		39 00 00 40 00 00 02 6F 05
		39 00 00 40 00 00 04 B8 3C 00 00
		39 00 00 40 00 00 02 6F 08
		39 00 00 40 00 00 03 B8 FF DC
		39 00 00 40 00 00 02 6F 0A
		39 00 00 40 00 00 04 B8 3D 00 00
		39 00 00 40 00 00 02 6F 0D
		39 00 00 00 00 00 03 B8 FF DC
		39 00 00 00 14 00 02 9D AA
		39 00 00 00 00 00 06 F0 55 AA 52 08 04
		39 00 00 40 00 00 02 C2 11
		39 00 00 40 00 00 02 6F 01
		39 00 00 40 00 00 03 B5 00 14
		39 00 00 40 00 00 02 6F 0C
		39 00 00 40 00 00 04 B6 00 00 00
		39 00 00 40 00 00 02 6F 0F
		39 00 00 40 00 00 04 B6 1C AB 80
		39 00 00 40 00 00 02 6F 18
		39 00 00 40 00 00 04 B6 1D 00 00
		39 00 00 40 00 00 02 6F 1B
		39 00 00 40 00 00 04 B6 0D D5 80
		39 00 00 40 00 00 02 6F 03
		39 00 00 40 00 00 02 B5 03
		39 00 00 40 00 00 02 6F 00
		39 00 00 40 00 00 04 B8 2B 00 00
		39 00 00 40 00 00 02 6F 03
		39 00 00 40 00 00 03 B8 0F FE
		39 00 00 40 00 00 02 6F 05
		39 00 00 40 00 00 04 B8 2B 10 00
		39 00 00 40 00 00 02 6F 08
		39 00 00 40 00 00 03 B8 03 A3
		39 00 00 40 00 00 02 6F 0A
		39 00 00 40 00 00 04 B8 2B 20 00
		39 00 00 40 00 00 02 6F 0D
		39 00 00 40 00 00 03 B8 00 4F
		39 00 00 40 00 00 02 6F 0F
		39 00 00 40 00 00 04 B8 2B 30 00
		39 00 00 40 00 00 02 6F 12
		39 00 00 40 00 00 03 B8 03 A3
		39 00 00 00 00 00 06 F0 55 AA 52 08 04
		39 00 00 40 00 00 02 6F 06
		39 00 00 40 00 00 02 B5 00
		39 00 00 40 00 00 05 FF AA 55 A5 81
		39 00 00 40 00 00 02 6F 0C
		39 00 00 40 00 00 02 FD 40
		39 00 00 40 00 00 03 51 00 00
		39 00 00 40 00 00 06 A3 84 4D BF CD BF
		39 00 00 40 00 00 06 F0 55 AA 52 08 00
		39 00 00 40 00 00 02 6F 30
		39 00 00 40 00 00 02 C0 38
		39 00 00 40 00 00 02 6F 59
		39 00 00 40 00 00 04 D5 00 1F 00
		39 00 00 40 00 00 06 F0 55 AA 52 08 00
		39 00 00 40 00 00 02 6F 1C
		39 00 00 40 00 00 11 BA 01 01 01 01 01 00 00 00 01 00 00 00 00 00 00 00
		39 00 00 40 00 00 06 F0 55 AA 52 08 01
		39 00 00 40 00 00 02 DD 5E
		39 00 00 40 00 00 06 F0 55 AA 52 08 00
		39 00 00 40 00 00 03 B2 09 60
		39 00 00 40 00 00 06 F0 55 AA 52 08 01
		39 00 00 40 00 00 02 6F 03
		39 00 00 40 00 00 02 C7 47
		39 00 00 40 00 00 06 F0 55 AA 52 08 01
		39 00 00 40 00 00 02 6F 41
		39 00 00 40 00 00 02 BB 57
		39 00 00 40 00 00 02 6F 47
		39 00 00 40 00 00 02 BB 4A
		39 00 00 40 00 00 02 6F 5F
		39 00 00 40 00 00 02 BB 57
		39 00 00 40 00 00 02 6F 65
		39 00 00 40 00 00 02 BB 4A
		39 00 00 40 00 00 05 FF AA 55 A5 80
		39 00 00 40 00 00 02 6F 29
		39 00 00 40 00 00 03 F8 0B B5
		39 00 00 40 00 00 02 6F 0D
		39 00 00 40 00 00 03 F8 01 3E
		39 00 00 40 00 00 02 6F 08
		39 00 00 40 00 00 08 F6 70 07 70 70 70 70 70
		39 00 00 40 00 00 02 68 00
		39 00 00 40 00 00 02 6F 01
		39 00 00 40 00 00 05 6B 01 E8 05 D0
		39 00 00 40 00 00 02 6F 05
		39 00 00 40 00 00 02 6D 77
		39 00 00 40 00 00 05 FF AA 55 A5 81
		39 00 00 40 00 00 02 6F 0A
		39 00 00 40 00 00 02 FD 00
		39 00 00 40 00 00 02 6F 0D
		39 00 00 40 00 00 02 FB 80
		39 00 00 40 00 00 02 6F 0D
		39 00 00 40 00 00 02 FE 83
		39 00 00 40 00 00 02 6F 10
		39 00 00 40 00 00 03 FE 07 FF
		39 00 00 40 00 00 05 FF AA 55 A5 82
		39 00 00 40 00 00 02 6F 11
		39 00 00 40 00 00 02 F8 0F
		39 00 00 40 00 00 02 17 30
		39 00 00 40 00 00 02 26 00
		39 00 00 40 00 00 02 5F 10
		39 00 00 40 00 00 02 2F 00
		39 00 00 40 00 00 05 2A 00 00 09 B3
		39 00 00 40 00 00 05 2B 00 00 08 B7

		39 00 00 40 00 00 06 F0 55 AA 52 08 00
		39 00 00 40 00 00 02 6F CC
		39 00 00 40 00 00 02 B2 00
		39 00 00 40 00 00 02 6F 04
		39 00 00 40 00 00 02 35 03
		39 00 00 40 00 00 02 53 28
		39 00 00 40 00 00 02 5A 00
		39 00 00 40 00 00 02 2F 30
		39 00 00 40 00 00 03 6D 01 01
		39 00 00 40 00 00 02 6F 06
		39 00 00 40 00 00 02 6D 00
		39 00 00 40 00 00 06 F0 55 AA 52 08 00
		39 00 00 40 00 00 02 6F DE
		39 00 00 40 00 00 02 BA 00
		39 00 00 40 00 00 02 6F 08
		39 00 00 40 00 00 02 B2 C0
		39 00 00 40 00 00 02 8C 00
		39 00 00 40 00 00 06 F0 55 AA 52 08 00
		39 00 00 40 00 00 02 6F 05
		39 00 00 00 00 00 03 B2 04 04

		39 00 00 40 00 00 03 90 03 43
		39 00 00 40 00 00 13 91 AB 28 00 08 C2 00 03 6D 01 01 00 11 0D B7 05 87 10 F0
		39 00 00 40 00 00 05 FF AA 55 A5 84
		39 00 00 00 00 00 02 F2 15
                05 00 00 00 78 00 01 11
		39 00 00 40 00 00 06 A3 84 4D BF CD BF
		39 00 00 40 00 00 02 6F 05
		39 00 00 40 00 00 0E A3 02 04 B5 02 03 00 03 00 00 00 00 00 00
		39 00 00 40 00 00 02 6F 12
		39 00 00 40 00 00 07 A3 01 00 9D 00 00 AA
		39 00 00 40 00 00 02 6F A1
		39 00 00 40 00 00 0E A3 02 04 B5 02 03 00 0C 00 00 00 00 00 00
		39 00 00 40 00 00 02 6F AE
		39 00 00 40 00 00 07 A3 01 00 9D 00 00 AA
                05 00 00 00 00 00 01 29];	/* display on */
		qcom,mdss-dsi-off-command = [
			05 00 00 00 00 00 01 28		/* display_off */
			05 00 00 00 78 00 01 10];	/* enter sleep mode */

		qcom,mdss-dsi-on-command-state = "dsi_lp_mode";
		qcom,mdss-dsi-off-command-state = "dsi_lp_mode";
		qcom,mdss-dsi-timing-switch-command-state =
			"dsi_hs_mode";
		qcom,compression-mode = "dsc";
		/* Why QCOM doesn't use this, even it used 2 encoder
		 * as for that dsi_sw43404_amoled_cmd, for ex */
		/* qcom,mdss-dsc-encoders = <2>; */
		qcom,mdss-dsc-version = <0x11>;
		qcom,mdss-dsc-slice-height = <8>;
		qcom,mdss-dsc-slice-width = <1242>;
		qcom,mdss-dsc-slice-per-pkt = <2>;
		qcom,mdss-dsc-bit-per-component = <10>;
		qcom,mdss-dsc-bit-per-pixel = <8>;
		qcom,mdss-dsc-block-prediction-enable;
		qcom,mdss-dsc-novateck-ic;


		qcom,mdss-dsi-pcd-check-enable-command = [
			39 00 00 40 00 00 06 F0 55 AA 52 08 01
			39 00 00 40 00 00 02 6F 01
			39 00 00 00 00 00 06 D0 80 00 30 00 01
			];
		qcom,mdss-dsi-pcd-check-enable-command-state = "dsi_hs_mode";
		qcom,mdss-dsi-pcd-check-disable-command = [
			39 00 00 40 00 00 06 F0 55 AA 52 08 01
			39 00 00 40 00 00 02 6F 01
			39 00 00 00 00 00 06 D0 00 00 30 00 01
			];
		qcom,mdss-dsi-pcd-check-disable-command-state = "dsi_hs_mode";
	};

	timing@4{
		qcom,mdss-dsi-cmd-mode;
		qcom,mdss-dsi-panel-framerate = <24>;
		qcom,mdss-dsi-panel-width = <2484>;
		qcom,mdss-dsi-panel-height = <2232>;
		qcom,mdss-dsi-h-front-porch = <42>;
		qcom,mdss-dsi-h-back-porch = <32>;
		qcom,mdss-dsi-h-pulse-width = <16>;
		qcom,mdss-dsi-h-sync-skew = <0>;
		qcom,mdss-dsi-h-sync-pulse = <0>;
		qcom,mdss-dsi-v-back-porch = <40>;
		qcom,mdss-dsi-v-front-porch = <32>;
		qcom,mdss-dsi-v-pulse-width = <2>;
		qcom,mdss-dsi-h-left-border = <0>;
		qcom,mdss-dsi-h-right-border = <0>;
		qcom,mdss-dsi-v-top-border = <0>;
		qcom,mdss-dsi-v-bottom-border = <0>;
		qcom,mdss-dsi-timing-switch-command = [
			39 00 00 40 00 00 06 F0 55 AA 52 08 00
			39 00 00 40 00 00 02 6F CC
			39 00 00 40 00 00 02 B2 00
			39 00 00 40 00 00 02 6B 00
			39 00 00 40 00 00 02 6F 04
			39 00 00 40 00 00 02 35 04
			39 00 00 40 00 00 02 53 28
			39 00 00 40 00 00 02 5A 00
			39 00 00 40 00 00 02 2F 30
			39 00 00 40 00 00 03 6D 02 01
			39 00 00 40 00 00 02 6F 06
			39 00 00 40 00 00 02 6D 00
			39 00 00 40 00 00 06 F0 55 AA 52 08 00
			39 00 00 40 00 00 02 6F DE
			39 00 00 40 00 00 02 BA 00
			39 00 00 40 00 00 02 6F 08
			39 00 00 40 00 00 02 B2 C0
			39 00 00 40 00 00 02 8C 00
			39 00 00 40 00 00 06 F0 55 AA 52 08 00
			39 00 00 40 00 00 02 6F 05
			39 00 00 00 00 00 03 B2 05 05
		];
		qcom,mdss-dsi-on-command = [
		39 00 00 40 00 00 06 F0 55 AA 52 08 04
		39 00 00 40 00 00 02 C2 12
		39 00 00 40 00 00 02 6F 01
		39 00 00 40 00 00 03 B5 00 00
		39 00 00 40 00 00 02 6F 03
		39 00 00 40 00 00 02 B5 07
		39 00 00 40 00 00 02 6F 00
		39 00 00 40 00 00 04 B8 3B 00 00
		39 00 00 40 00 00 02 6F 03
		39 00 00 40 00 00 03 B8 FF DC
		39 00 00 40 00 00 02 6F 05
		39 00 00 40 00 00 04 B8 3C 00 00
		39 00 00 40 00 00 02 6F 08
		39 00 00 40 00 00 03 B8 FF DC
		39 00 00 40 00 00 02 6F 0A
		39 00 00 40 00 00 04 B8 3D 00 00
		39 00 00 40 00 00 02 6F 0D
		39 00 00 00 00 00 03 B8 FF DC
		39 00 00 00 14 00 02 9D AA
		39 00 00 00 00 00 06 F0 55 AA 52 08 04
		39 00 00 40 00 00 02 C2 11
		39 00 00 40 00 00 02 6F 01
		39 00 00 40 00 00 03 B5 00 14
		39 00 00 40 00 00 02 6F 0C
		39 00 00 40 00 00 04 B6 00 00 00
		39 00 00 40 00 00 02 6F 0F
		39 00 00 40 00 00 04 B6 1C AB 80
		39 00 00 40 00 00 02 6F 18
		39 00 00 40 00 00 04 B6 1D 00 00
		39 00 00 40 00 00 02 6F 1B
		39 00 00 40 00 00 04 B6 0D D5 80
		39 00 00 40 00 00 02 6F 03
		39 00 00 40 00 00 02 B5 03
		39 00 00 40 00 00 02 6F 00
		39 00 00 40 00 00 04 B8 2B 00 00
		39 00 00 40 00 00 02 6F 03
		39 00 00 40 00 00 03 B8 0F FE
		39 00 00 40 00 00 02 6F 05
		39 00 00 40 00 00 04 B8 2B 10 00
		39 00 00 40 00 00 02 6F 08
		39 00 00 40 00 00 03 B8 03 A3
		39 00 00 40 00 00 02 6F 0A
		39 00 00 40 00 00 04 B8 2B 20 00
		39 00 00 40 00 00 02 6F 0D
		39 00 00 40 00 00 03 B8 00 4F
		39 00 00 40 00 00 02 6F 0F
		39 00 00 40 00 00 04 B8 2B 30 00
		39 00 00 40 00 00 02 6F 12
		39 00 00 40 00 00 03 B8 03 A3
		39 00 00 00 00 00 06 F0 55 AA 52 08 04
		39 00 00 40 00 00 02 6F 06
		39 00 00 40 00 00 02 B5 00
		39 00 00 40 00 00 05 FF AA 55 A5 81
		39 00 00 40 00 00 02 6F 0C
		39 00 00 40 00 00 02 FD 40
		39 00 00 40 00 00 03 51 00 00
		39 00 00 40 00 00 06 A3 84 4D BF CD BF
		39 00 00 40 00 00 06 F0 55 AA 52 08 00
		39 00 00 40 00 00 02 6F 30
		39 00 00 40 00 00 02 C0 38
		39 00 00 40 00 00 02 6F 59
		39 00 00 40 00 00 04 D5 00 1F 00
		39 00 00 40 00 00 06 F0 55 AA 52 08 00
		39 00 00 40 00 00 02 6F 1C
		39 00 00 40 00 00 11 BA 01 01 01 01 01 00 00 00 01 00 00 00 00 00 00 00
		39 00 00 40 00 00 06 F0 55 AA 52 08 01
		39 00 00 40 00 00 02 DD 5E
		39 00 00 40 00 00 06 F0 55 AA 52 08 00
		39 00 00 40 00 00 03 B2 09 60
		39 00 00 40 00 00 06 F0 55 AA 52 08 01
		39 00 00 40 00 00 02 6F 03
		39 00 00 40 00 00 02 C7 47
		39 00 00 40 00 00 06 F0 55 AA 52 08 01
		39 00 00 40 00 00 02 6F 41
		39 00 00 40 00 00 02 BB 57
		39 00 00 40 00 00 02 6F 47
		39 00 00 40 00 00 02 BB 4A
		39 00 00 40 00 00 02 6F 5F
		39 00 00 40 00 00 02 BB 57
		39 00 00 40 00 00 02 6F 65
		39 00 00 40 00 00 02 BB 4A
		39 00 00 40 00 00 05 FF AA 55 A5 80
		39 00 00 40 00 00 02 6F 29
		39 00 00 40 00 00 03 F8 0B B5
		39 00 00 40 00 00 02 6F 0D
		39 00 00 40 00 00 03 F8 01 3E
		39 00 00 40 00 00 02 6F 08
		39 00 00 40 00 00 08 F6 70 07 70 70 70 70 70
		39 00 00 40 00 00 02 68 00
		39 00 00 40 00 00 02 6F 01
		39 00 00 40 00 00 05 6B 01 E8 05 D0
		39 00 00 40 00 00 02 6F 05
		39 00 00 40 00 00 02 6D 77
		39 00 00 40 00 00 05 FF AA 55 A5 81
		39 00 00 40 00 00 02 6F 0A
		39 00 00 40 00 00 02 FD 00
		39 00 00 40 00 00 02 6F 0D
		39 00 00 40 00 00 02 FB 80
		39 00 00 40 00 00 02 6F 0D
		39 00 00 40 00 00 02 FE 83
		39 00 00 40 00 00 02 6F 10
		39 00 00 40 00 00 03 FE 07 FF
		39 00 00 40 00 00 05 FF AA 55 A5 82
		39 00 00 40 00 00 02 6F 11
		39 00 00 40 00 00 02 F8 0F
		39 00 00 40 00 00 02 17 30
		39 00 00 40 00 00 02 26 00
		39 00 00 40 00 00 02 5F 10
		39 00 00 40 00 00 02 2F 00
		39 00 00 40 00 00 05 2A 00 00 09 B3
		39 00 00 40 00 00 05 2B 00 00 08 B7

		39 00 00 40 00 00 06 F0 55 AA 52 08 00
		39 00 00 40 00 00 02 6F CC
		39 00 00 40 00 00 02 B2 00
		39 00 00 40 00 00 02 6F 04
		39 00 00 40 00 00 02 35 04
		39 00 00 40 00 00 02 53 28
		39 00 00 40 00 00 02 5A 00
		39 00 00 40 00 00 02 2F 30
		39 00 00 40 00 00 03 6D 02 01
		39 00 00 40 00 00 02 6F 06
		39 00 00 40 00 00 02 6D 00
		39 00 00 40 00 00 06 F0 55 AA 52 08 00
		39 00 00 40 00 00 02 6F DE
		39 00 00 40 00 00 02 BA 00
		39 00 00 40 00 00 02 6F 08
		39 00 00 40 00 00 02 B2 C0
		39 00 00 40 00 00 02 8C 00
		39 00 00 40 00 00 06 F0 55 AA 52 08 00
		39 00 00 40 00 00 02 6F 05
		39 00 00 00 00 00 03 B2 05 05

		39 00 00 40 00 00 03 90 03 43
		39 00 00 40 00 00 13 91 AB 28 00 08 C2 00 03 6D 01 01 00 11 0D B7 05 87 10 F0
		39 00 00 40 00 00 05 FF AA 55 A5 84
		39 00 00 00 00 00 02 F2 15
                05 00 00 00 78 00 01 11
		39 00 00 40 00 00 06 A3 84 4D BF CD BF
		39 00 00 40 00 00 02 6F 05
		39 00 00 40 00 00 0E A3 02 04 B5 02 03 00 03 00 00 00 00 00 00
		39 00 00 40 00 00 02 6F 12
		39 00 00 40 00 00 07 A3 01 00 9D 00 00 AA
		39 00 00 40 00 00 02 6F A1
		39 00 00 40 00 00 0E A3 02 04 B5 02 03 00 0C 00 00 00 00 00 00
		39 00 00 40 00 00 02 6F AE
		39 00 00 40 00 00 07 A3 01 00 9D 00 00 AA
                05 00 00 00 00 00 01 29];	/* display on */
		qcom,mdss-dsi-off-command = [
			05 00 00 00 00 00 01 28		/* display_off */
			05 00 00 00 78 00 01 10];	/* enter sleep mode */

		qcom,mdss-dsi-on-command-state = "dsi_lp_mode";
		qcom,mdss-dsi-off-command-state = "dsi_lp_mode";
		qcom,mdss-dsi-timing-switch-command-state =
			"dsi_hs_mode";
		qcom,compression-mode = "dsc";
		/* Why QCOM doesn't use this, even it used 2 encoder
		 * as for that dsi_sw43404_amoled_cmd, for ex */
		/* qcom,mdss-dsc-encoders = <2>; */
		qcom,mdss-dsc-version = <0x11>;
		qcom,mdss-dsc-slice-height = <8>;
		qcom,mdss-dsc-slice-width = <1242>;
		qcom,mdss-dsc-slice-per-pkt = <2>;
		qcom,mdss-dsc-bit-per-component = <10>;
		qcom,mdss-dsc-bit-per-pixel = <8>;
		qcom,mdss-dsc-block-prediction-enable;
		qcom,mdss-dsc-novateck-ic;

		qcom,mdss-dsi-pcd-check-enable-command = [
			39 00 00 40 00 00 06 F0 55 AA 52 08 01
			39 00 00 40 00 00 02 6F 01
			39 00 00 00 00 00 06 D0 80 00 30 00 01
			];
		qcom,mdss-dsi-pcd-check-enable-command-state = "dsi_hs_mode";
		qcom,mdss-dsi-pcd-check-disable-command = [
			39 00 00 40 00 00 06 F0 55 AA 52 08 01
			39 00 00 40 00 00 02 6F 01
			39 00 00 00 00 00 06 D0 00 00 30 00 01
			];
		qcom,mdss-dsi-pcd-check-disable-command-state = "dsi_hs_mode";
	};

	timing@5{
		qcom,mdss-dsi-cmd-mode;
		qcom,mdss-dsi-panel-framerate = <120>;	/* Actually 10 hz*/
		qcom,mdss-dsi-panel-width = <2484>;
		qcom,mdss-dsi-panel-height = <2232>;
		qcom,mdss-dsi-h-front-porch = <42>;
		qcom,mdss-dsi-h-back-porch = <32>;
		qcom,mdss-dsi-h-pulse-width = <14>;
		qcom,mdss-dsi-h-sync-skew = <0>;
		qcom,mdss-dsi-h-sync-pulse = <0>;
		qcom,mdss-dsi-v-back-porch = <40>;
		qcom,mdss-dsi-v-front-porch = <32>;
		qcom,mdss-dsi-v-pulse-width = <2>;
		qcom,mdss-dsi-h-left-border = <0>;
		qcom,mdss-dsi-h-right-border = <0>;
		qcom,mdss-dsi-v-top-border = <0>;
		qcom,mdss-dsi-v-bottom-border = <0>;
		qcom,mdss-dsi-timing-switch-command = [
			39 00 00 40 00 00 06 F0 55 AA 52 08 00
			39 00 00 40 00 00 02 6F CC
			39 00 00 40 00 00 02 B2 00
			39 00 00 40 00 00 02 6B 00
			39 00 00 40 00 00 02 6F 04
			39 00 00 40 00 00 02 35 00
			39 00 00 40 00 00 02 53 20
			39 00 00 40 00 00 02 5A 00
			39 00 00 40 00 00 02 6F 06
			39 00 00 40 00 00 02 6D 00
			39 00 00 40 00 00 02 2F 30
			39 00 00 40 00 00 03 6D 03 01
			39 00 00 40 00 00 06 F0 55 AA 52 08 00
			39 00 00 40 00 00 02 6F DE
			39 00 00 40 00 00 02 BA 00
			39 00 00 40 00 00 02 6F 08
			39 00 00 40 00 00 02 B2 C0
			39 00 00 00 00 00 02 8C 00
		];
		qcom,mdss-dsi-on-command = [
		39 00 00 40 00 00 06 F0 55 AA 52 08 04
		39 00 00 40 00 00 02 C2 12
		39 00 00 40 00 00 02 6F 01
		39 00 00 40 00 00 03 B5 00 00
		39 00 00 40 00 00 02 6F 03
		39 00 00 40 00 00 02 B5 07
		39 00 00 40 00 00 02 6F 00
		39 00 00 40 00 00 04 B8 3B 00 00
		39 00 00 40 00 00 02 6F 03
		39 00 00 40 00 00 03 B8 FF DC
		39 00 00 40 00 00 02 6F 05
		39 00 00 40 00 00 04 B8 3C 00 00
		39 00 00 40 00 00 02 6F 08
		39 00 00 40 00 00 03 B8 FF DC
		39 00 00 40 00 00 02 6F 0A
		39 00 00 40 00 00 04 B8 3D 00 00
		39 00 00 40 00 00 02 6F 0D
		39 00 00 00 00 00 03 B8 FF DC
		39 00 00 00 14 00 02 9D AA
		39 00 00 00 00 00 06 F0 55 AA 52 08 04
		39 00 00 40 00 00 02 C2 11
		39 00 00 40 00 00 02 6F 01
		39 00 00 40 00 00 03 B5 00 14
		39 00 00 40 00 00 02 6F 0C
		39 00 00 40 00 00 04 B6 00 00 00
		39 00 00 40 00 00 02 6F 0F
		39 00 00 40 00 00 04 B6 1C AB 80
		39 00 00 40 00 00 02 6F 18
		39 00 00 40 00 00 04 B6 1D 00 00
		39 00 00 40 00 00 02 6F 1B
		39 00 00 40 00 00 04 B6 0D D5 80
		39 00 00 40 00 00 02 6F 03
		39 00 00 40 00 00 02 B5 03
		39 00 00 40 00 00 02 6F 00
		39 00 00 40 00 00 04 B8 2B 00 00
		39 00 00 40 00 00 02 6F 03
		39 00 00 40 00 00 03 B8 0F FE
		39 00 00 40 00 00 02 6F 05
		39 00 00 40 00 00 04 B8 2B 10 00
		39 00 00 40 00 00 02 6F 08
		39 00 00 40 00 00 03 B8 03 A3
		39 00 00 40 00 00 02 6F 0A
		39 00 00 40 00 00 04 B8 2B 20 00
		39 00 00 40 00 00 02 6F 0D
		39 00 00 40 00 00 03 B8 00 4F
		39 00 00 40 00 00 02 6F 0F
		39 00 00 40 00 00 04 B8 2B 30 00
		39 00 00 40 00 00 02 6F 12
		39 00 00 40 00 00 03 B8 03 A3
		39 00 00 00 00 00 06 F0 55 AA 52 08 04
		39 00 00 40 00 00 02 6F 06
		39 00 00 40 00 00 02 B5 00
		39 00 00 40 00 00 05 FF AA 55 A5 81
		39 00 00 40 00 00 02 6F 0C
		39 00 00 40 00 00 02 FD 40
		39 00 00 40 00 00 03 51 00 00
		39 00 00 40 00 00 06 A3 84 4D BF CD BF
		39 00 00 40 00 00 06 F0 55 AA 52 08 00
		39 00 00 40 00 00 02 6F 30
		39 00 00 40 00 00 02 C0 38
		39 00 00 40 00 00 02 6F 59
		39 00 00 40 00 00 04 D5 00 1F 00
		39 00 00 40 00 00 06 F0 55 AA 52 08 00
		39 00 00 40 00 00 02 6F 1C
		39 00 00 40 00 00 11 BA 01 01 01 01 01 00 00 00 01 00 00 00 00 00 00 00
		39 00 00 40 00 00 06 F0 55 AA 52 08 01
		39 00 00 40 00 00 02 DD 5E
		39 00 00 40 00 00 06 F0 55 AA 52 08 00
		39 00 00 40 00 00 03 B2 09 60
		39 00 00 40 00 00 06 F0 55 AA 52 08 01
		39 00 00 40 00 00 02 6F 03
		39 00 00 40 00 00 02 C7 47
		39 00 00 40 00 00 06 F0 55 AA 52 08 01
		39 00 00 40 00 00 02 6F 41
		39 00 00 40 00 00 02 BB 57
		39 00 00 40 00 00 02 6F 47
		39 00 00 40 00 00 02 BB 4A
		39 00 00 40 00 00 02 6F 5F
		39 00 00 40 00 00 02 BB 57
		39 00 00 40 00 00 02 6F 65
		39 00 00 40 00 00 02 BB 4A
		39 00 00 40 00 00 05 FF AA 55 A5 80
		39 00 00 40 00 00 02 6F 29
		39 00 00 40 00 00 03 F8 0B B5
		39 00 00 40 00 00 02 6F 0D
		39 00 00 40 00 00 03 F8 01 3E
		39 00 00 40 00 00 02 6F 08
		39 00 00 40 00 00 08 F6 70 07 70 70 70 70 70
		39 00 00 40 00 00 02 68 00
		39 00 00 40 00 00 02 6F 01
		39 00 00 40 00 00 05 6B 01 E8 05 D0
		39 00 00 40 00 00 02 6F 05
		39 00 00 40 00 00 02 6D 77
		39 00 00 40 00 00 05 FF AA 55 A5 81
		39 00 00 40 00 00 02 6F 0A
		39 00 00 40 00 00 02 FD 00
		39 00 00 40 00 00 02 6F 0D
		39 00 00 40 00 00 02 FB 80
		39 00 00 40 00 00 02 6F 0D
		39 00 00 40 00 00 02 FE 83
		39 00 00 40 00 00 02 6F 10
		39 00 00 40 00 00 03 FE 07 FF
		39 00 00 40 00 00 05 FF AA 55 A5 82
		39 00 00 40 00 00 02 6F 11
		39 00 00 40 00 00 02 F8 0F
		39 00 00 40 00 00 02 17 30
		39 00 00 40 00 00 02 26 00
		39 00 00 40 00 00 02 5F 10
		39 00 00 40 00 00 02 2F 00
		39 00 00 40 00 00 05 2A 00 00 09 B3
		39 00 00 40 00 00 05 2B 00 00 08 B7

		39 00 00 40 00 00 06 F0 55 AA 52 08 00
		39 00 00 40 00 00 02 6F CC
		39 00 00 40 00 00 02 B2 00
		39 00 00 40 00 00 02 6F 04
		39 00 00 40 00 00 02 35 00
		39 00 00 40 00 00 02 53 20
		39 00 00 40 00 00 02 5A 00
		39 00 00 40 00 00 02 6F 06
		39 00 00 40 00 00 02 6D 00
		39 00 00 40 00 00 02 2F 30
		39 00 00 40 00 00 03 6D 03 01
		39 00 00 40 00 00 06 F0 55 AA 52 08 00
		39 00 00 40 00 00 02 6F DE
		39 00 00 40 00 00 02 BA 00
		39 00 00 40 00 00 02 6F 08
		39 00 00 40 00 00 02 B2 C0
		39 00 00 00 00 00 02 8C 00

		39 00 00 40 00 00 03 90 03 43
		39 00 00 40 00 00 13 91 AB 28 00 08 C2 00 03 6D 01 01 00 11 0D B7 05 87 10 F0
		39 00 00 40 00 00 05 FF AA 55 A5 84
		39 00 00 00 00 00 02 F2 15
                05 00 00 00 78 00 01 11
		39 00 00 40 00 00 06 A3 84 4D BF CD BF
		39 00 00 40 00 00 02 6F 05
		39 00 00 40 00 00 0E A3 02 04 B5 02 03 00 03 00 00 00 00 00 00
		39 00 00 40 00 00 02 6F 12
		39 00 00 40 00 00 07 A3 01 00 9D 00 00 AA
		39 00 00 40 00 00 02 6F A1
		39 00 00 40 00 00 0E A3 02 04 B5 02 03 00 0C 00 00 00 00 00 00
		39 00 00 40 00 00 02 6F AE
		39 00 00 40 00 00 07 A3 01 00 9D 00 00 AA
                05 00 00 00 00 00 01 29];	/* display on */
		qcom,mdss-dsi-off-command = [
			05 00 00 00 00 00 01 28		/* display_off */
			05 00 00 00 78 00 01 10];	/* enter sleep mode */

		qcom,mdss-dsi-on-command-state = "dsi_lp_mode";
		qcom,mdss-dsi-off-command-state = "dsi_lp_mode";
		qcom,mdss-dsi-timing-switch-command-state =
			"dsi_hs_mode";
		qcom,compression-mode = "dsc";
		/* Why QCOM doesn't use this, even it used 2 encoder
		 * as for that dsi_sw43404_amoled_cmd, for ex */
		/* qcom,mdss-dsc-encoders = <2>; */
		qcom,mdss-dsc-version = <0x11>;
		qcom,mdss-dsc-slice-height = <8>;
		qcom,mdss-dsc-slice-width = <1242>;
		qcom,mdss-dsc-slice-per-pkt = <2>;
		qcom,mdss-dsc-bit-per-component = <10>;
		qcom,mdss-dsc-bit-per-pixel = <8>;
		qcom,mdss-dsc-block-prediction-enable;
		qcom,mdss-dsc-novateck-ic;

		qcom,mdss-dsi-pcd-check-enable-command = [
			39 00 00 40 00 00 06 F0 55 AA 52 08 01
			39 00 00 40 00 00 02 6F 01
			39 00 00 00 00 00 06 D0 80 00 30 00 01
			];
		qcom,mdss-dsi-pcd-check-enable-command-state = "dsi_hs_mode";
		qcom,mdss-dsi-pcd-check-disable-command = [
			39 00 00 40 00 00 06 F0 55 AA 52 08 01
			39 00 00 40 00 00 02 6F 01
			39 00 00 00 00 00 06 D0 00 00 30 00 01
			];
		qcom,mdss-dsi-pcd-check-disable-command-state = "dsi_hs_mode";
	};

	timing@6{
		qcom,mdss-dsi-cmd-mode;
		qcom,mdss-dsi-panel-framerate = <120>;	/* Actually 1 hz*/
		qcom,mdss-dsi-panel-width = <2484>;
		qcom,mdss-dsi-panel-height = <2232>;
		qcom,mdss-dsi-h-front-porch = <42>;
		qcom,mdss-dsi-h-back-porch = <32>;
		qcom,mdss-dsi-h-pulse-width = <12>;
		qcom,mdss-dsi-h-sync-skew = <0>;
		qcom,mdss-dsi-h-sync-pulse = <0>;
		qcom,mdss-dsi-v-back-porch = <40>;
		qcom,mdss-dsi-v-front-porch = <32>;
		qcom,mdss-dsi-v-pulse-width = <2>;
		qcom,mdss-dsi-h-left-border = <0>;
		qcom,mdss-dsi-h-right-border = <0>;
		qcom,mdss-dsi-v-top-border = <0>;
		qcom,mdss-dsi-v-bottom-border = <0>;
		qcom,mdss-dsi-timing-switch-command = [
			39 00 00 40 00 00 06 F0 55 AA 52 08 00
			39 00 00 40 00 00 02 6F CC
			39 00 00 40 00 00 02 B2 00
			39 00 00 40 00 00 02 6B 00
			39 00 00 40 00 00 02 6F 04
			39 00 00 40 00 00 02 35 00
			39 00 00 40 00 00 02 53 20
			39 00 00 40 00 00 02 5A 00
			39 00 00 40 00 00 02 6F 06
			39 00 00 40 00 00 02 6D 00
			39 00 00 40 00 00 02 2F 30
			39 00 00 40 00 00 03 6D 04 01
			39 00 00 40 00 00 06 F0 55 AA 52 08 00
			39 00 00 40 00 00 02 6F DE
			39 00 00 40 00 00 02 BA 00
			39 00 00 40 00 00 02 6F 08
			39 00 00 40 00 00 02 B2 C0
			39 00 00 00 00 00 02 8C 00
		];
		qcom,mdss-dsi-on-command = [
		39 00 00 40 00 00 06 F0 55 AA 52 08 04
		39 00 00 40 00 00 02 C2 12
		39 00 00 40 00 00 02 6F 01
		39 00 00 40 00 00 03 B5 00 00
		39 00 00 40 00 00 02 6F 03
		39 00 00 40 00 00 02 B5 07
		39 00 00 40 00 00 02 6F 00
		39 00 00 40 00 00 04 B8 3B 00 00
		39 00 00 40 00 00 02 6F 03
		39 00 00 40 00 00 03 B8 FF DC
		39 00 00 40 00 00 02 6F 05
		39 00 00 40 00 00 04 B8 3C 00 00
		39 00 00 40 00 00 02 6F 08
		39 00 00 40 00 00 03 B8 FF DC
		39 00 00 40 00 00 02 6F 0A
		39 00 00 40 00 00 04 B8 3D 00 00
		39 00 00 40 00 00 02 6F 0D
		39 00 00 00 00 00 03 B8 FF DC
		39 00 00 00 14 00 02 9D AA
		39 00 00 00 00 00 06 F0 55 AA 52 08 04
		39 00 00 40 00 00 02 C2 11
		39 00 00 40 00 00 02 6F 01
		39 00 00 40 00 00 03 B5 00 14
		39 00 00 40 00 00 02 6F 0C
		39 00 00 40 00 00 04 B6 00 00 00
		39 00 00 40 00 00 02 6F 0F
		39 00 00 40 00 00 04 B6 1C AB 80
		39 00 00 40 00 00 02 6F 18
		39 00 00 40 00 00 04 B6 1D 00 00
		39 00 00 40 00 00 02 6F 1B
		39 00 00 40 00 00 04 B6 0D D5 80
		39 00 00 40 00 00 02 6F 03
		39 00 00 40 00 00 02 B5 03
		39 00 00 40 00 00 02 6F 00
		39 00 00 40 00 00 04 B8 2B 00 00
		39 00 00 40 00 00 02 6F 03
		39 00 00 40 00 00 03 B8 0F FE
		39 00 00 40 00 00 02 6F 05
		39 00 00 40 00 00 04 B8 2B 10 00
		39 00 00 40 00 00 02 6F 08
		39 00 00 40 00 00 03 B8 03 A3
		39 00 00 40 00 00 02 6F 0A
		39 00 00 40 00 00 04 B8 2B 20 00
		39 00 00 40 00 00 02 6F 0D
		39 00 00 40 00 00 03 B8 00 4F
		39 00 00 40 00 00 02 6F 0F
		39 00 00 40 00 00 04 B8 2B 30 00
		39 00 00 40 00 00 02 6F 12
		39 00 00 40 00 00 03 B8 03 A3
		39 00 00 00 00 00 06 F0 55 AA 52 08 04
		39 00 00 40 00 00 02 6F 06
		39 00 00 40 00 00 02 B5 00
		39 00 00 40 00 00 05 FF AA 55 A5 81
		39 00 00 40 00 00 02 6F 0C
		39 00 00 40 00 00 02 FD 40
		39 00 00 40 00 00 03 51 00 00
		39 00 00 40 00 00 06 A3 84 4D BF CD BF
		39 00 00 40 00 00 06 F0 55 AA 52 08 00
		39 00 00 40 00 00 02 6F 30
		39 00 00 40 00 00 02 C0 38
		39 00 00 40 00 00 02 6F 59
		39 00 00 40 00 00 04 D5 00 1F 00
		39 00 00 40 00 00 06 F0 55 AA 52 08 00
		39 00 00 40 00 00 02 6F 1C
		39 00 00 40 00 00 11 BA 01 01 01 01 01 00 00 00 01 00 00 00 00 00 00 00
		39 00 00 40 00 00 06 F0 55 AA 52 08 01
		39 00 00 40 00 00 02 DD 5E
		39 00 00 40 00 00 06 F0 55 AA 52 08 00
		39 00 00 40 00 00 03 B2 09 60
		39 00 00 40 00 00 06 F0 55 AA 52 08 01
		39 00 00 40 00 00 02 6F 03
		39 00 00 40 00 00 02 C7 47
		39 00 00 40 00 00 06 F0 55 AA 52 08 01
		39 00 00 40 00 00 02 6F 41
		39 00 00 40 00 00 02 BB 57
		39 00 00 40 00 00 02 6F 47
		39 00 00 40 00 00 02 BB 4A
		39 00 00 40 00 00 02 6F 5F
		39 00 00 40 00 00 02 BB 57
		39 00 00 40 00 00 02 6F 65
		39 00 00 40 00 00 02 BB 4A
		39 00 00 40 00 00 05 FF AA 55 A5 80
		39 00 00 40 00 00 02 6F 29
		39 00 00 40 00 00 03 F8 0B B5
		39 00 00 40 00 00 02 6F 0D
		39 00 00 40 00 00 03 F8 01 3E
		39 00 00 40 00 00 02 6F 08
		39 00 00 40 00 00 08 F6 70 07 70 70 70 70 70
		39 00 00 40 00 00 02 68 00
		39 00 00 40 00 00 02 6F 01
		39 00 00 40 00 00 05 6B 01 E8 05 D0
		39 00 00 40 00 00 02 6F 05
		39 00 00 40 00 00 02 6D 77
		39 00 00 40 00 00 05 FF AA 55 A5 81
		39 00 00 40 00 00 02 6F 0A
		39 00 00 40 00 00 02 FD 00
		39 00 00 40 00 00 02 6F 0D
		39 00 00 40 00 00 02 FB 80
		39 00 00 40 00 00 02 6F 0D
		39 00 00 40 00 00 02 FE 83
		39 00 00 40 00 00 02 6F 10
		39 00 00 40 00 00 03 FE 07 FF
		39 00 00 40 00 00 05 FF AA 55 A5 82
		39 00 00 40 00 00 02 6F 11
		39 00 00 40 00 00 02 F8 0F
		39 00 00 40 00 00 02 17 30
		39 00 00 40 00 00 02 26 00
		39 00 00 40 00 00 02 5F 10
		39 00 00 40 00 00 02 2F 00
		39 00 00 40 00 00 05 2A 00 00 09 B3
		39 00 00 40 00 00 05 2B 00 00 08 B7

		39 00 00 40 00 00 06 F0 55 AA 52 08 00
		39 00 00 40 00 00 02 6F CC
		39 00 00 40 00 00 02 B2 00
		39 00 00 40 00 00 02 6F 04
		39 00 00 40 00 00 02 35 00
		39 00 00 40 00 00 02 53 20
		39 00 00 40 00 00 02 5A 00
		39 00 00 40 00 00 02 6F 06
		39 00 00 40 00 00 02 6D 00
		39 00 00 40 00 00 02 2F 30
		39 00 00 40 00 00 03 6D 04 01
		39 00 00 40 00 00 06 F0 55 AA 52 08 00
		39 00 00 40 00 00 02 6F DE
		39 00 00 40 00 00 02 BA 00
		39 00 00 40 00 00 02 6F 08
		39 00 00 40 00 00 02 B2 C0
		39 00 00 00 00 00 02 8C 00

		39 00 00 40 00 00 03 90 03 43
		39 00 00 40 00 00 13 91 AB 28 00 08 C2 00 03 6D 01 01 00 11 0D B7 05 87 10 F0
		39 00 00 40 00 00 05 FF AA 55 A5 84
		39 00 00 00 00 00 02 F2 15
                05 00 00 00 78 00 01 11
		39 00 00 40 00 00 06 A3 84 4D BF CD BF
		39 00 00 40 00 00 02 6F 05
		39 00 00 40 00 00 0E A3 02 04 B5 02 03 00 03 00 00 00 00 00 00
		39 00 00 40 00 00 02 6F 12
		39 00 00 40 00 00 07 A3 01 00 9D 00 00 AA
		39 00 00 40 00 00 02 6F A1
		39 00 00 40 00 00 0E A3 02 04 B5 02 03 00 0C 00 00 00 00 00 00
		39 00 00 40 00 00 02 6F AE
		39 00 00 40 00 00 07 A3 01 00 9D 00 00 AA
                05 00 00 00 00 00 01 29];	/* display on */
		qcom,mdss-dsi-off-command = [
			05 00 00 00 00 00 01 28		/* display_off */
			05 00 00 00 78 00 01 10];	/* enter sleep mode */

		qcom,mdss-dsi-on-command-state = "dsi_lp_mode";
		qcom,mdss-dsi-off-command-state = "dsi_lp_mode";
		qcom,mdss-dsi-timing-switch-command-state =
			"dsi_hs_mode";
		qcom,compression-mode = "dsc";
		/* Why QCOM doesn't use this, even it used 2 encoder
		 * as for that dsi_sw43404_amoled_cmd, for ex */
		/* qcom,mdss-dsc-encoders = <2>; */
		qcom,mdss-dsc-version = <0x11>;
		qcom,mdss-dsc-slice-height = <8>;
		qcom,mdss-dsc-slice-width = <1242>;
		qcom,mdss-dsc-slice-per-pkt = <2>;
		qcom,mdss-dsc-bit-per-component = <10>;
		qcom,mdss-dsc-bit-per-pixel = <8>;
		qcom,mdss-dsc-block-prediction-enable;
		qcom,mdss-dsc-novateck-ic;

		qcom,mdss-dsi-pcd-check-enable-command = [
			39 00 00 40 00 00 06 F0 55 AA 52 08 01
			39 00 00 40 00 00 02 6F 01
			39 00 00 00 00 00 06 D0 80 00 30 00 01
			];
		qcom,mdss-dsi-pcd-check-enable-command-state = "dsi_hs_mode";
		qcom,mdss-dsi-pcd-check-disable-command = [
			39 00 00 40 00 00 06 F0 55 AA 52 08 01
			39 00 00 40 00 00 02 6F 01
			39 00 00 00 00 00 06 D0 00 00 30 00 01
			];
		qcom,mdss-dsi-pcd-check-disable-command-state = "dsi_hs_mode";
	};

};

};

};
